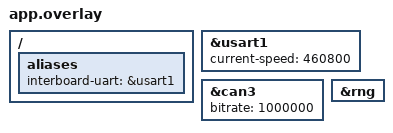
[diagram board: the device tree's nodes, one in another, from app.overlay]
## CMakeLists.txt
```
cmake_minimum_required(VERSION 3.20.0)
find_package(Zephyr REQUIRED HINTS $ENV{ZEPHYR_BASE})
project(big_yaw_interboard)
target_sources(app PRIVATE src/main.cpp)
```

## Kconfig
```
mainmenu "Manual interboard big Yaw without IMU"

config BIG_YAW_INTERBOARD_CHASSIS_ROLE
    bool "Build the chassis board driving the real big-Yaw motor"
    default n

source "Kconfig.zephyr"
```

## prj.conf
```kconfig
CONFIG_CPP=y
CONFIG_STD_CPP20=y
CONFIG_REQUIRES_FULL_LIBCPP=y
CONFIG_MAIN_STACK_SIZE=8192
CONFIG_HEAP_MEM_POOL_SIZE=0
CONFIG_LOG=y
CONFIG_LOG_MODE_DEFERRED=y
CONFIG_CBPRINTF_FP_SUPPORT=y
CONFIG_SERIAL=y
CONFIG_UART_ASYNC_API=y
CONFIG_NOCACHE_MEMORY=y
CONFIG_CAN=y
CONFIG_FPU=y
CONFIG_FPU_SHARING=y
CONFIG_ENTROPY_GENERATOR=y
CONFIG_SKYWALKER_DRIVER_MOTOR=y
CONFIG_SKYWALKER_MOTOR_DM=y
CONFIG_SKYWALKER_LIB_CONTROL=y
CONFIG_SKYWALKER_LIB_MOTOR_CONTROL=y
CONFIG_SKYWALKER_LIB_COMMUNICATION=y
CONFIG_SKYWALKER_UART_TRANSPORT=y
CONFIG_SKYWALKER_REMOTE_DR16=y
CONFIG_SKYWALKER_REMOTE_RECEIVER=y
CONFIG_SKYWALKER_INTERBOARD=y
CONFIG_SKYWALKER_INTERBOARD_ENDPOINT=y
CONFIG_SKYWALKER_REFEREE=n
CONFIG_SKYWALKER_LIB_ROBOTICS=y
CONFIG_SKYWALKER_ROBOTICS_COMMAND=n
CONFIG_SKYWALKER_ROBOTICS_SWERVE=n
CONFIG_SKYWALKER_ROBOTICS_BIG_YAW=y
CONFIG_SKYWALKER_IMU=n
```

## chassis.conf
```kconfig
CONFIG_BIG_YAW_INTERBOARD_CHASSIS_ROLE=y
```

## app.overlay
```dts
/* USART1: PA9 TX -> peer PA10 RX, PA10 RX <- peer PA9 TX; common GND.
 * RC remains on the gimbal board's UART5; USART10 is the log console.
 * Motor ownership follows ../common/chassis_can.hpp (currently CAN3).
 */
/ { aliases { interboard-uart = &usart1; }; };
&usart1 { current-speed = <460800>; };
&can3 { status = "okay"; bitrate = <1000000>; };
&rng { status = "okay"; };
```

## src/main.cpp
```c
#include "../../common/operator_controls.hpp"
#include <communication/interboard/uart_interboard_transport.hpp>
#include <core/clock.hpp>
#include <zephyr/kernel.h>
#include <zephyr/logging/log.h>
#if defined(CONFIG_BIG_YAW_INTERBOARD_CHASSIS_ROLE)
#include "../../common/chassis_can.hpp"
#include <cerrno>
#include <drivers/motor/can_bus.hpp>
#include <robotics/vehicle/big_yaw_profile.hpp>
#if defined(CONFIG_BOARD_DM_MC02)
#include <zephyr/drivers/regulator.h>
#endif
#else
#include "../../common/rc_controls.hpp"
#endif

LOG_MODULE_REGISTER(big_yaw_interboard, LOG_LEVEL_INF);
using namespace skywalker;
using namespace skywalker::robotics;

namespace {
#if defined(CONFIG_BIG_YAW_INTERBOARD_CHASSIS_ROLE)
constexpr auto role = BoardRole::ChassisController;
#else
constexpr auto role = BoardRole::GimbalController;
// Output joint velocity, rad/s; retains the standalone big_yaw bench limit.
constexpr float manual_rate_max_rad_s = 0.1f;
#endif
communication::AsyncUart::DmaBuffers link_dma __nocache;
communication::UartInterBoardTransport transport(DEVICE_DT_GET(DT_ALIAS(interboard_uart)), link_dma);
communication::InterBoardEndpoint endpoint(transport, {role});

void communicationTask(void *, void *, void *) {
    for (;;) {
        endpoint.poll(k_uptime_get());
        k_sleep(K_MSEC(1));
    }
}
} // namespace

K_THREAD_DEFINE(big_yaw_link_worker, 4096, communicationTask, nullptr, nullptr, nullptr, 6, K_FP_REGS, 0);

int main() {
    LOG_INF("manual bigYaw role=%u UART1=460800; no IMU", unsigned(role));
#if defined(CONFIG_BIG_YAW_INTERBOARD_CHASSIS_ROLE)
    static motor::Motor drive(vehicle::bigYawHardware());
    static motor::CanBus bus(samples::chassis::big_yaw_can);
    static BigYawExecutor axis(drive, vehicle::bigYawMotorConfig(), vehicle::bigYawExecutionConfig());
    int setup_error = -ENODEV;
    if (vehicle::connections_confirmed) {
        setup_error = bus.attach(drive);
        if (setup_error == 0)
            setup_error = bus.start();
#if defined(CONFIG_BOARD_DM_MC02)
        if (setup_error == 0)
            setup_error = regulator_enable(DEVICE_DT_GET(DT_NODELABEL(power1)));
#endif
        if (setup_error == 0)
            setup_error = axis.begin();
    }
    const bool started = setup_error == 0;
    LOG_INF("motor bus=%s id=%u master=%u confirmed=%d setup=%d", samples::chassis::big_yaw_can->name,
            unsigned(vehicle::big_yaw.id), unsigned(vehicle::big_yaw.master_id), vehicle::connections_confirmed,
            setup_error);
    samples::control::OperatorControlConsumer operator_controls;
    std::uint64_t next_log_ms = 0;
    int commit_error = 0;
    for (;;) {
        const auto now = core::monotonicTimeUs(), ms = now / 1000;
        const auto rx = endpoint.snapshot();
        const auto controls = operator_controls.update(rx, ms);
        BigYawExecutionInputs input{};
        input.request = rx.big_yaw_request;
        if (!controls.run_allowed) {
            input.request.mode = BigYawMode::Disabled;
            input.request.target_rate_rad_s = 0;
        }
        input.local_boot_id = rx.local_boot_id;
        input.peer_online = rx.online;
        input.transport_ready = started;
        input.emergency_stop = controls.emergency_stop;
        input.clear_estop = controls.clear_estop;
        if (started) {
            axis.update(input, now);
            commit_error = bus.commit().error;
        }
        else {
            axis.suspend(now, WaitReason::Configuration, setup_error, true);
        }
        // Feedback comes only from the real execution owner and motor snapshot.
        endpoint.setBigYawFeedback(axis.feedback());
        if (ms >= next_log_ms) {
            next_log_ms = ms + 200;
            const auto state = axis.status();
            const auto feedback = axis.feedback();
            LOG_INF(
                "online=%d operator=%d run=%d source=%u target=%f actual=%f ready=%d valid=%d state=%u reason=%u error=%d commit=%d link=%d rejected=%u",
                rx.online, rx.operator_control_valid, controls.run_allowed, input.request.source_sequence,
                double(input.request.target_rate_rad_s), double(feedback.actual_rate_rad_s), feedback.ready,
                feedback.valid, unsigned(state.state), unsigned(state.reason), state.error, commit_error, rx.error,
                rx.rejected_frames);
        }
        k_sleep(K_MSEC(5));
    }
#else
    static communication::AsyncUart::DmaBuffers remote_dma __nocache;
    static communication::RemoteReceiver remote(DEVICE_DT_GET(DT_ALIAS(remote_uart)), remote_dma,
                                                samples::control::receiverConfig());
    const int ret = remote.start();
    if (ret < 0) {
        LOG_ERR("remote start failed: %d", ret);
        return ret;
    }
    LOG_INF("RC both Down + centered 500ms, then left Middle, Up=manual; right Down spin 0.1 rad/s; left Down stops");
    samples::control::RcControlAdapter controls;
    samples::control::OperatorControlPublisher operator_controls;
    communication::RemoteReceiver::Snapshot remote_cache{};
    std::uint64_t next_log_ms = 0;
    for (;;) {
        const auto ms = static_cast<std::uint64_t>(k_uptime_get());
        (void)remote.snapshot(remote_cache);
        const auto &rc = controls.update(remote_cache.remote, ms);
        // A link loss or peer reboot withdraws the RC gate before this cycle's
        // velocity is generated. Motor recovery alone never withdraws intent.
        if (operator_controls.publish(endpoint, rc.run_allowed, false, rc.remote.stamp, rc.clear_event_id,
                                      rc.clear_stamp, ms))
            controls.withdraw();
        const auto rx = endpoint.snapshot();
        const bool run = rc.fresh && rc.run_allowed && rx.online;
        BigYawRequest request{};
        // FollowCenter is the existing v4 velocity-request wire mode; this
        // entry generates manual velocity and does not run a centering loop.
        request.mode = run ? BigYawMode::FollowCenter : BigYawMode::Disabled;
        request.target_rate_rad_s = run && rc.spin_requested ? manual_rate_max_rad_s : 0;
        request.source_sequence = rc.remote.stamp.sequence;
        request.stamp = rc.remote.stamp;
        request.receiver_boot_id = rx.peer.sender_boot_id;
        // Explicit manual bench permission, not referee or IMU authority.
        request.permission = {rc.fresh, run, rc.remote.stamp};
        // Keep the original RC timestamp: repeated snapshots and wire retries
        // must not renew source/command/permission freshness.
        endpoint.submitBigYaw(request);
        if (ms >= next_log_ms) {
            next_log_ms = ms + 200;
            const auto &feedback = rx.big_yaw_feedback;
            LOG_INF(
                "online=%d rc=%d run=%d source=%u target=%f peerActual=%f peerReady=%d peerValid=%d link=%d rejected=%u",
                rx.online, rc.fresh, run, request.source_sequence, double(request.target_rate_rad_s),
                double(feedback.actual_rate_rad_s), feedback.ready, feedback.valid, rx.error, rx.rejected_frames);
        }
        k_sleep(K_MSEC(5));
    }
#endif
}
```
